# SWM330 register map
File version: 1.0
CPU: CM0 r1p0, little endian, 2 interrupt priority bits
Registers are 32-bit, read-write, no defined reset value unless marked. A register's access mark holds for its fields unless they carry their own. Offsets are from the block's base; [hi:lo] are bit positions; lines under a group give offsets from that group; {n}, {i} and the like mark numbered series; 'fields as' and 'values as' point back to an identical list.

## ADC0 — Registers group
Base 0x40043800
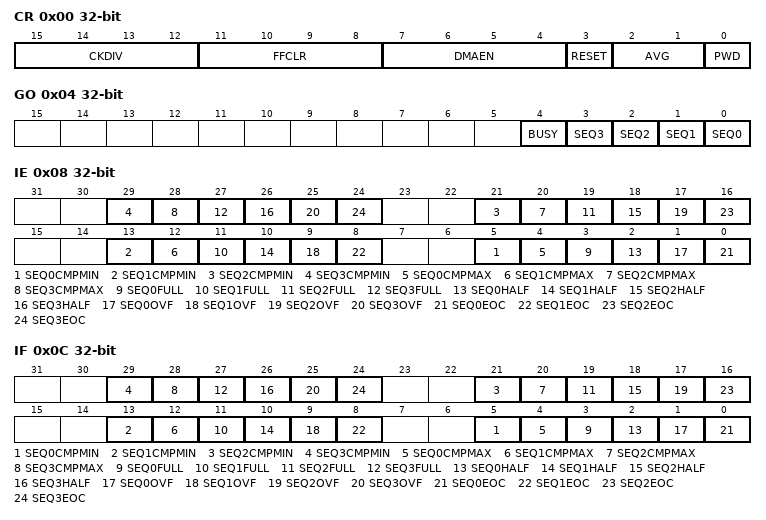
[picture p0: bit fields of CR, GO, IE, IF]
0x00 CR
  [15:12] CKDIV, [11:8] FFCLR, [7:4] DMAEN, [3] RESET, [2:1] AVG, [0] PWD
0x04 GO
  [4] BUSY, [n] SEQ{n} (n=0..3)
0x08 IE
  [8n+5] SEQ{n}CMPMIN (n=0..3), [8n+4] SEQ{n}CMPMAX (n=0..3), [8n+3] SEQ{n}FULL (n=0..3), [8n+2] SEQ{n}HALF (n=0..3), [8n+1] SEQ{n}OVF (n=0..3), [8n] SEQ{n}EOC (n=0..3)
0x0C IF
  fields as IE
{0x10+0x10*i} SEQ{i} group (i=0..3) — register cluster
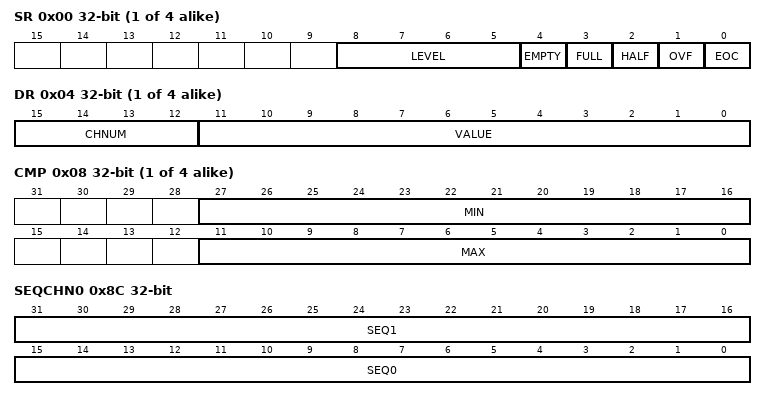
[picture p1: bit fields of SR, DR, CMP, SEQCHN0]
  0x00 SR
    [8:5] LEVEL, [4] EMPTY, [3] FULL, [2] HALF, [1] OVF, [0] EOC
  0x04 DR
    [15:12] CHNUM, [11:0] VALUE
  0x08 CMP
    [27:16] MIN, [11:0] MAX
0x8C SEQCHN0
  [31:16] SEQ1, [15:0] SEQ0
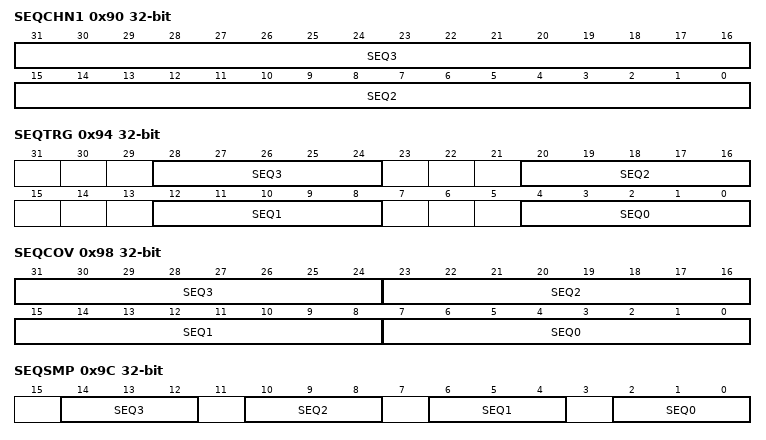
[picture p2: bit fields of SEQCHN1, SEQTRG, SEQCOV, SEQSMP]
0x90 SEQCHN1
  [31:16] SEQ3, [15:0] SEQ2
0x94 SEQTRG
  [8n+4:8n] SEQ{n} (n=0..3)
0x98 SEQCOV
  [8n+7:8n] SEQ{n} (n=0..3)
0x9C SEQSMP
  [4n+2:4n] SEQ{n} (n=0..3)

## PWM0 — Registers group
Base 0x40045000
Same registers: PWM1 0x40045080
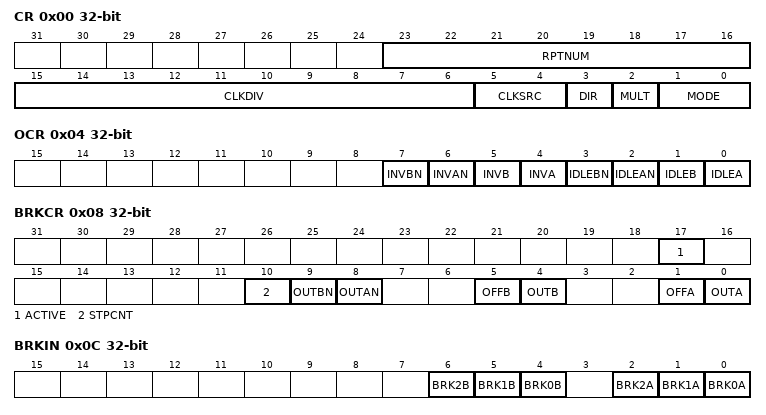
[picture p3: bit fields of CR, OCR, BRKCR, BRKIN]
0x00 CR
  [23:16] RPTNUM, [15:6] CLKDIV, [5:4] CLKSRC, [3] DIR, [2] MULT, [1:0] MODE
0x04 OCR
  [7] INVBN, [6] INVAN, [5] INVB, [4] INVA, [3] IDLEBN, [2] IDLEAN, [1] IDLEB, [0] IDLEA
0x08 BRKCR
  [17] ACTIVE, [10] STPCNT, [9] OUTBN, [8] OUTAN, [5] OFFB, [4] OUTB, [1] OFFA, [0] OUTA
0x0C BRKIN
  [6] BRK2B, [5] BRK1B, [4] BRK0B, [2] BRK2A, [1] BRK1A, [0] BRK0A
0x20 PERIOD
0x24 CMPA
0x28 CMPB
0x2C DZA
0x30 DZB
0x34 CMPA2
0x38 CMPB2
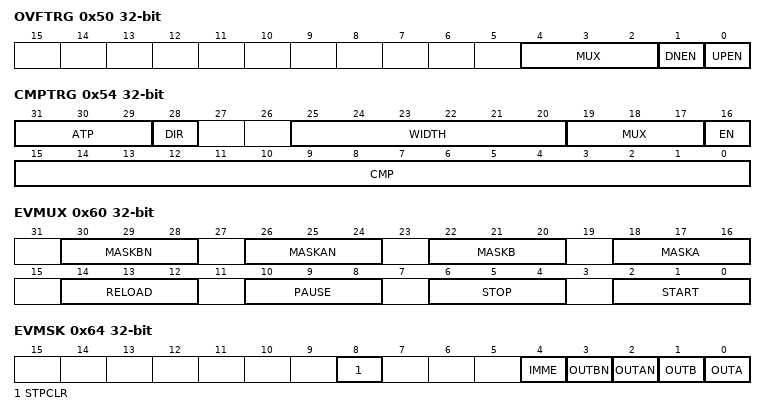
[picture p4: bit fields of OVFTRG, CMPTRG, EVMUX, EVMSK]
0x50 OVFTRG
  [4:2] MUX, [1] DNEN, [0] UPEN
0x54 CMPTRG
  [31:29] ATP, [28] DIR, [25:20] WIDTH, [19:17] MUX, [16] EN, [15:0] CMP
0x60 EVMUX
  [30:28] MASKBN, [26:24] MASKAN, [22:20] MASKB, [18:16] MASKA, [14:12] RELOAD, [10:8] PAUSE, [6:4] STOP, [2:0] START
0x64 EVMSK
  [8] STPCLR, [4] IMME, [3] OUTBN, [2] OUTAN, [1] OUTB, [0] OUTA
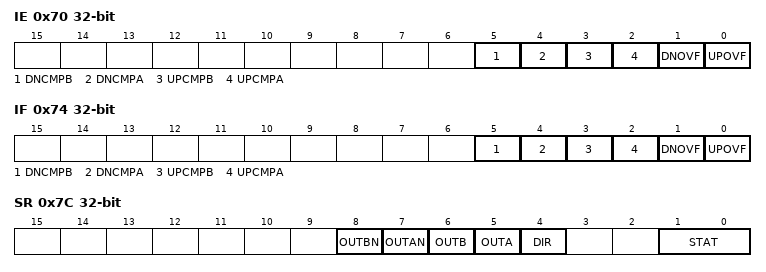
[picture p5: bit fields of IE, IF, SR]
0x70 IE
  [5] DNCMPB, [4] DNCMPA, [3] UPCMPB, [2] UPCMPA, [1] DNOVF, [0] UPOVF
0x74 IF
  [5] DNCMPB, [4] DNCMPA, [3] UPCMPB, [2] UPCMPA, [1] DNOVF, [0] UPOVF
0x78 VALUE
0x7C SR
  [8] OUTBN, [7] OUTAN, [6] OUTB, [5] OUTA, [4] DIR, [1:0] STAT

## PWMG — Registers group
Base 0x40045400
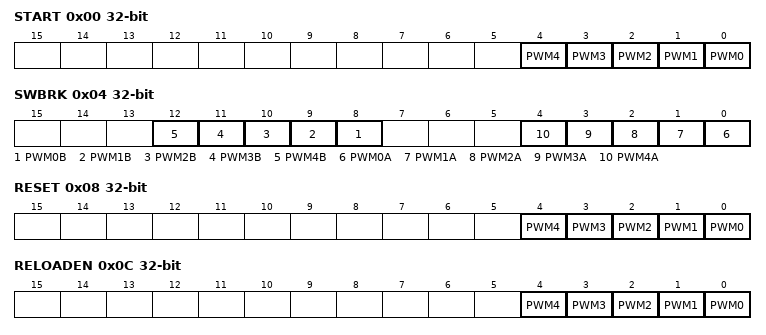
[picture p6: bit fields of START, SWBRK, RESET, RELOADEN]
0x00 START
  [n] PWM{n} (n=0..4)
0x04 SWBRK
  [n+8] PWM{n}B (n=0..4), [n] PWM{n}A (n=0..4)
0x08 RESET
  [n] PWM{n} (n=0..4)
0x0C RELOADEN
  [n] PWM{n} (n=0..4)
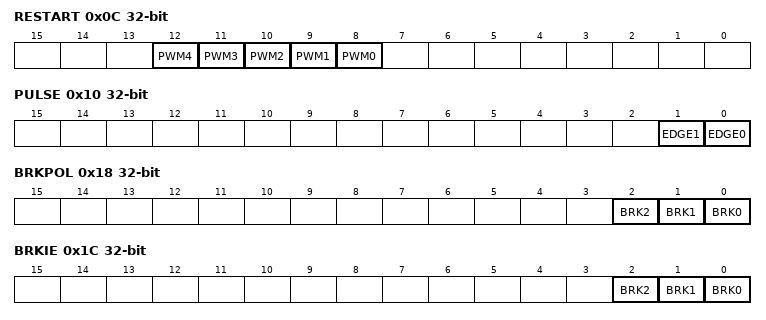
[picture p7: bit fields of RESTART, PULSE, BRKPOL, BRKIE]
0x0C RESTART (alternate view of RELOADEN)
  [n+8] PWM{n} (n=0..4)
0x10 PULSE
  [1] EDGE1, [0] EDGE0
0x14 FILTER
0x18 BRKPOL
  [2] BRK2, [1] BRK1, [0] BRK0
0x1C BRKIE
  [2] BRK2, [1] BRK1, [0] BRK0
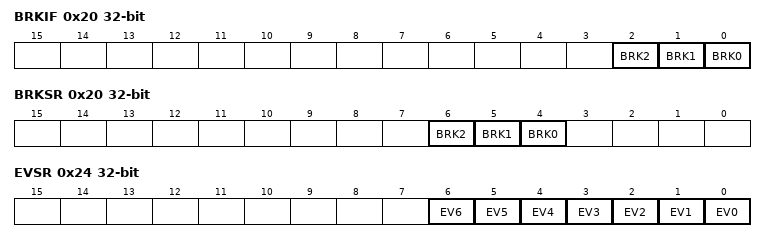
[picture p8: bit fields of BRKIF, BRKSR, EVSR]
0x20 BRKIF
  [2] BRK2, [1] BRK1, [0] BRK0
0x20 BRKSR (alternate view of BRKIF)
  [6] BRK2, [5] BRK1, [4] BRK0
0x24 EVSR
  [n] EV{n} (n=0..6)

## DAC0 — Registers group
Base 0x40043000
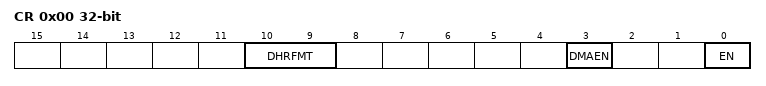
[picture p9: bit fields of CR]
0x00 CR
  [10:9] DHRFMT, [3] DMAEN, [0] EN
0x04 SR ro
  [0] DHRFULL
0x08 SWTRG wo
0x0C DHR

## DMA — Registers group
Base 0x40000800
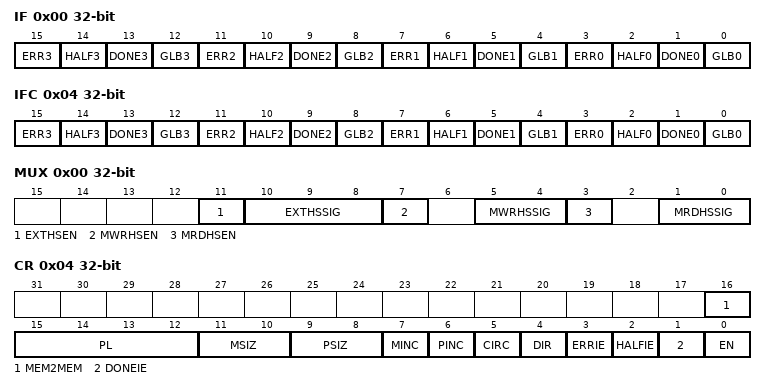
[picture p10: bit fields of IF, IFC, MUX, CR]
0x00 IF
  [4n+3] ERR{n} (n=0..3), [4n+2] HALF{n} (n=0..3), [4n+1] DONE{n} (n=0..3), [4n] GLB{n} (n=0..3)
0x04 IFC
  fields as IF
0x10 CH0 group — register cluster
  0x00 MUX
    [11] EXTHSEN, [10:8] EXTHSSIG, [7] MWRHSEN, [5:4] MWRHSSIG, [3] MRDHSEN, [1:0] MRDHSSIG
  0x04 CR
    [16] MEM2MEM, [15:12] PL, [11:10] MSIZ, [9:8] PSIZ, [7] MINC, [6] PINC, [5] CIRC, [4] DIR, [3] ERRIE, [2] HALFIE, [1] DONEIE, [0] EN
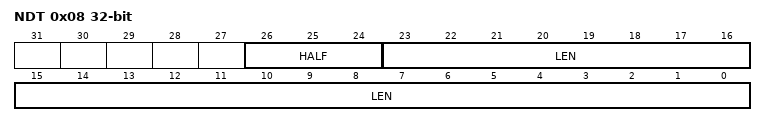
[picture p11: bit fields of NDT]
  0x08 NDT
    [26:24] HALF, [23:0] LEN
  0x0C PAR
  0x10 MAR
0x30 CH1 group — register cluster
  0x00 MUX
    fields as CH0.MUX
  0x04 CR
    fields as CH0.CR
  0x08 NDT
    [26:24] HALF, [23:0] LEN
  0x0C PAR
  0x10 MAR

## RDMA — Registers group
Base 0x40005000
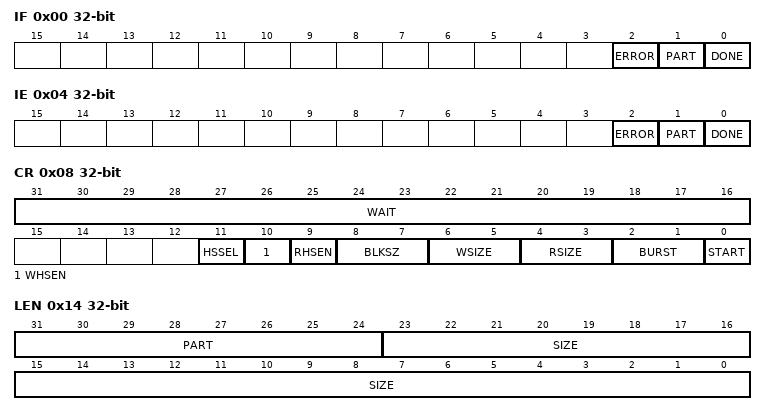
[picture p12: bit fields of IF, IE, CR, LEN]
0x00 IF
  [2] ERROR, [1] PART, [0] DONE
0x04 IE
  [2] ERROR, [1] PART, [0] DONE
0x08 CR
  [31:16] WAIT, [11] HSSEL, [10] WHSEN, [9] RHSEN, [8:7] BLKSZ, [6:5] WSIZE, [4:3] RSIZE, [2:1] BURST, [0] START
0x0C SRC
0x10 DES
0x14 LEN
  [31:24] PART, [23:0] SIZE
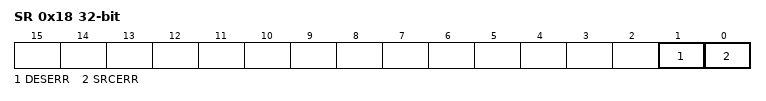
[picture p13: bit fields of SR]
0x18 SR
  [1] DESERR, [0] SRCERR
